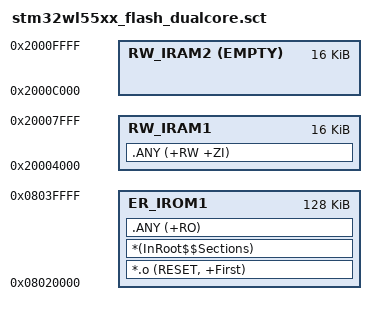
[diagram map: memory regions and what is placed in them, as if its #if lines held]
#! armclang --target=arm-arm-none-eabi -march=armv7-M -E -x c
; *************************************************************
; *** Scatter-Loading Description File generated by uVision ***
; *************************************************************

; Memory Regions
;***** FLASH Part dedicated to CPU1 *****
#define ROM_CPU1_START 					0x08000000
#define ROM_CPU1_LENGTH					0x00020000
;***** FLASH Part dedicated to CPU2 *****
#define ROM_CPU2_START 					0x08020000
#define ROM_CPU2_LENGTH 				0x00020000

;***** SRAM1 dedicated to CPU1 *****
#define SRAM1_CPU1_START 				0x20000000 
#define SRAM1_CPU1_LENGTH    			0x00004000
;***** SRAM1 dedicated to CPU2 ***** 
#define SRAM1_CPU2_START  				0x20004000
#define SRAM1_CPU2_LENGTH    			0x00004000

;***** SRAM2 dedicated to CPU1 *****
#define SRAM2_CPU1_START  				0x20008000
#define SRAM2_CPU1_LENGTH    			0x00004000
;***** SRAM2 dedicated to CPU2 *****
#define SRAM2_CPU2_START  				0x2000C000
#define SRAM2_CPU2_LENGTH   			0x00004000

#ifdef CPU2
LR_IROM1 ROM_CPU2_START ROM_CPU2_LENGTH  {    ; load region size_region
  ; FLASH part dedicated to M0+
  ER_IROM1 ROM_CPU2_START ROM_CPU2_LENGTH  {  ; load address execution address
   *.o (RESET, +First)
   *(InRoot$$Sections)
   .ANY (+RO)
  }
  ; Non-backup SRAM1 dedicated to M0+
  RW_IRAM1 SRAM1_CPU2_START SRAM1_CPU2_LENGTH  {  ; RW data
   .ANY (+RW +ZI)
  }
  ; Backup SRAM2 dedicated to M0+
  RW_IRAM2 SRAM2_CPU2_START EMPTY SRAM2_CPU2_LENGTH  {  ; RW data
  }
}

#else
LR_IROM1 ROM_CPU1_START ROM_CPU1_LENGTH  {    ; load region size_region
  ; FLASH part dedicated to M4
  ER_IROM1 ROM_CPU1_START ROM_CPU1_LENGTH  {  ; load address execution address
   *.o (RESET, +First)
   *(InRoot$$Sections)
   .ANY (+RO)
  }
  ; Non-backup SRAM1 dedicated to M4
  RW_IRAM1 SRAM1_CPU1_START SRAM1_CPU1_LENGTH  {  ; RW data
   .ANY (+RW +ZI)
  }
  ; Backup SRAM2 dedicated to M4
  RW_IRAM2 SRAM2_CPU1_START EMPTY SRAM2_CPU1_LENGTH  {  ; RW data
  }
}

#endif
